VERSION ""

NS_ :

BS_:

BU_: PDM ATCCR ATCCF

BO_ 3221225472 VECTOR__INDEPENDENT_SIG_MSG: 0 Vector__XXX
 SG_ ATCCR_counterMsg465 : 0|4@1+ (1,0) [0|15] "" Vector__XXX
 SG_ PWM_wpPWM : 0|8@1+ (1,0) [0|255] "%" Vector__XXX
 SG_ PDM_fanLeftPWM : 0|8@1+ (1,0) [0|255] "%" Vector__XXX
 SG_ PDM_fanRightPWM : 0|8@1+ (1,0) [0|255] "%" Vector__XXX
 SG_ PDM_keepAliveVoltMin : 0|16@1- (0.001,0) [-32.768|32.767] "V" Vector__XXX
 SG_ PDM_keepAliveVoltAvg : 0|16@1- (0.001,0) [-32.768|32.767] "V" Vector__XXX
 SG_ PDM_keepAliveVoltMax : 0|16@1- (0.001,0) [-32.768|32.767] "V" Vector__XXX
 SG_ PDM_fuelVoltMin : 0|16@1- (0.001,0) [-32.768|32.767] "V" Vector__XXX
 SG_ PDM_fuelVoltAvg : 0|16@1- (0.001,0) [-32.768|32.767] "V" Vector__XXX
 SG_ PDM_fuelVoltMax : 0|16@1- (0.001,0) [-32.768|32.767] "V" Vector__XXX
 SG_ PDM_starterRelayVoltAvg : 0|16@1- (0.001,0) [-32.768|32.767] "V" Vector__XXX
 SG_ PDM_brakelightVoltAvg : 0|16@1- (0.001,0) [-32.768|32.767] "V" Vector__XXX
 SG_ PDM_dataVoltMin : 0|16@1- (0.001,0) [-32.768|32.767] "V" Vector__XXX
 SG_ PDM_dataVoltAvg : 0|16@1- (0.001,0) [-32.768|32.767] "V" Vector__XXX
 SG_ PDM_dataVoltMax : 0|16@1- (0.001,0) [-32.768|32.767] "V" Vector__XXX
 SG_ PDM_mainVoltMin : 0|16@1- (0.001,0) [-32.768|32.767] "V" Vector__XXX
 SG_ PDM_mainVoltAvg : 0|16@1- (0.001,0) [-32.768|32.767] "V" Vector__XXX
 SG_ PDM_mainVoltMax : 0|16@1- (0.001,0) [-32.768|32.767] "V" Vector__XXX
 SG_ PDM_wpVoltMin : 0|16@1- (0.001,0) [-32.768|32.767] "V" Vector__XXX
 SG_ PDM_wpVoltAvg : 0|16@1- (0.001,0) [-32.768|32.767] "V" Vector__XXX
 SG_ PDM_wpVoltMax : 0|16@1- (0.001,0) [-32.768|32.767] "V" Vector__XXX
 SG_ PDM_fanLeftVoltMin : 0|16@1- (0.001,0) [-32.768|32.767] "V" Vector__XXX
 SG_ PDM_fanLeftVoltAvg : 0|16@1- (0.001,0) [-32.768|32.767] "V" Vector__XXX
 SG_ PDM_fanLeftVoltMax : 0|16@1- (0.001,0) [-32.768|32.767] "V" Vector__XXX
 SG_ PDM_fanRightVoltMin : 0|16@1- (0.001,0) [-32.768|32.767] "V" Vector__XXX
 SG_ PDM_fanRightVoltAvg : 0|16@1- (0.001,0) [-32.768|32.767] "V" Vector__XXX
 SG_ PDM_fanRightVoltMax : 0|16@1- (0.001,0) [-32.768|32.767] "V" Vector__XXX
 SG_ PDM_pdmVoltMin : 0|16@1- (0.001,0) [-32.768|32.767] "V" Vector__XXX
 SG_ PDM_pdmVoltAvg : 0|16@1- (0.001,0) [-32.768|32.767] "V" Vector__XXX
 SG_ PDM_pdmVoltMax : 0|16@1- (0.001,0) [-32.768|32.767] "V" Vector__XXX
 SG_ PDM_fuelCurrentMin : 0|16@1- (0.01,0) [-327.68|327.67] "A" Vector__XXX
 SG_ PDM_fuelCurrentAvg : 0|16@1- (0.01,0) [-327.68|327.67] "A" Vector__XXX
 SG_ PDM_fuelCurrentMax : 0|16@1- (0.01,0) [-327.68|327.67] "A" Vector__XXX
 SG_ PDM_wpCurrentMin : 0|16@1- (0.01,0) [-327.68|327.67] "A" Vector__XXX
 SG_ PDM_wpCurrentAvg : 0|16@1- (0.01,0) [-327.68|327.67] "A" Vector__XXX
 SG_ PDM_wpCurrentMax : 0|16@1- (0.01,0) [-327.68|327.67] "A" Vector__XXX
 SG_ PDM_fanLeftCurrentMin : 0|16@1- (0.01,0) [-327.68|327.67] "A" Vector__XXX
 SG_ PDM_fanLeftCurrentAvg : 0|16@1- (0.01,0) [-327.68|327.67] "A" Vector__XXX
 SG_ PDM_fanLeftCurrentMax : 0|16@1- (1,0) [-32768|32767] "A" Vector__XXX
 SG_ PDM_fanRightCurrentMin : 0|16@1- (0.01,0) [-327.68|327.67] "A" Vector__XXX
 SG_ PDM_fanRightCurrentAvg : 0|16@1- (0.01,0) [-327.68|327.67] "A" Vector__XXX
 SG_ PDM_fanRightCurrentMax : 0|16@1- (0.01,0) [-327.68|327.67] "A" Vector__XXX
 SG_ ATCCF_counterMsg415 : 0|4@1+ (1,0) [0|15] "" Vector__XXX
 SG_ PDM_pdmCurrentMin : 0|16@1- (0.01,0) [-327.68|327.67] "A" Vector__XXX
 SG_ PDM_pdmCurrentAvg : 0|16@1- (0.01,0) [-327.68|327.67] "A" Vector__XXX
 SG_ PDM_pdmCurrentMax : 0|16@1- (0.01,0) [-327.68|327.67] "A" Vector__XXX
 SG_ PDM_boardTemp : 0|16@1- (0.1,0) [-3276.8|3276.7] "C" Vector__XXX

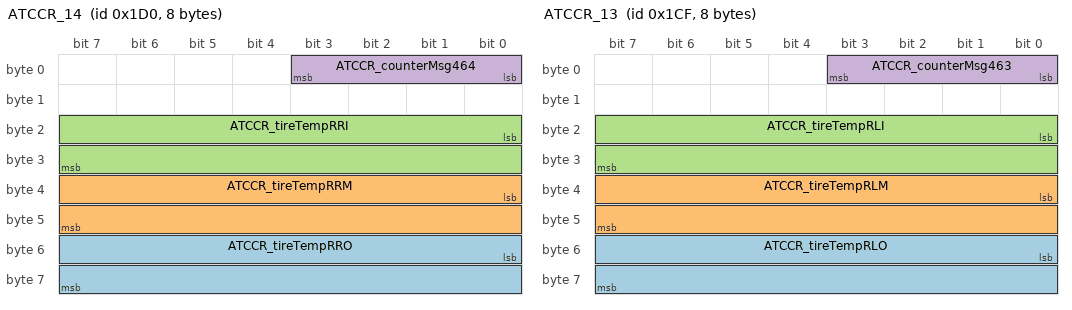
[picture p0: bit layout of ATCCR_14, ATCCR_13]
BO_ 464 ATCCR_14: 8 ATCCR
 SG_ ATCCR_tireTempRRO : 48|16@1- (0.1,0) [-3276.8|3276.7] "C" Vector__XXX
 SG_ ATCCR_tireTempRRM : 32|16@1- (0.1,0) [-3276.8|3276.7] "C" Vector__XXX
 SG_ ATCCR_tireTempRRI : 16|16@1- (0.1,0) [-3276.8|3276.7] "C" Vector__XXX
 SG_ ATCCR_counterMsg464 : 0|4@1+ (1,0) [0|15] "" Vector__XXX

BO_ 463 ATCCR_13: 8 ATCCR
 SG_ ATCCR_tireTempRLO : 48|16@1- (0.1,0) [-3276.8|3276.7] "C" Vector__XXX
 SG_ ATCCR_tireTempRLM : 32|16@1- (0.1,0) [-3276.8|3276.7] "C" Vector__XXX
 SG_ ATCCR_tireTempRLI : 16|16@1- (0.1,0) [-3276.8|3276.7] "C" Vector__XXX
 SG_ ATCCR_counterMsg463 : 0|4@1+ (1,0) [0|15] "" Vector__XXX

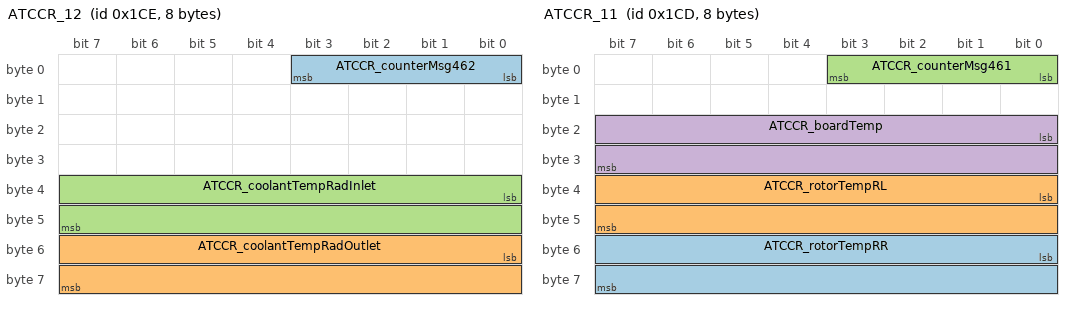
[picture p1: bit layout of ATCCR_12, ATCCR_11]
BO_ 462 ATCCR_12: 8 ATCCR
 SG_ ATCCR_counterMsg462 : 0|4@1+ (1,0) [0|15] "" Vector__XXX
 SG_ ATCCR_coolantTempRadOutlet : 48|16@1- (0.1,0) [-3276.8|3276.7] "C" Vector__XXX
 SG_ ATCCR_coolantTempRadInlet : 32|16@1- (0.1,0) [-3276.8|3276.7] "C" Vector__XXX

BO_ 461 ATCCR_11: 8 ATCCR
 SG_ ATCCR_rotorTempRR : 48|16@1- (0.1,0) [-3276.8|3276.7] "C" Vector__XXX
 SG_ ATCCR_rotorTempRL : 32|16@1- (0.1,0) [-3276.8|3276.7] "C" Vector__XXX
 SG_ ATCCR_counterMsg461 : 0|4@1+ (1,0) [0|15] "" Vector__XXX
 SG_ ATCCR_boardTemp : 16|16@1- (0.1,0) [-3276.8|3276.7] "C" Vector__XXX

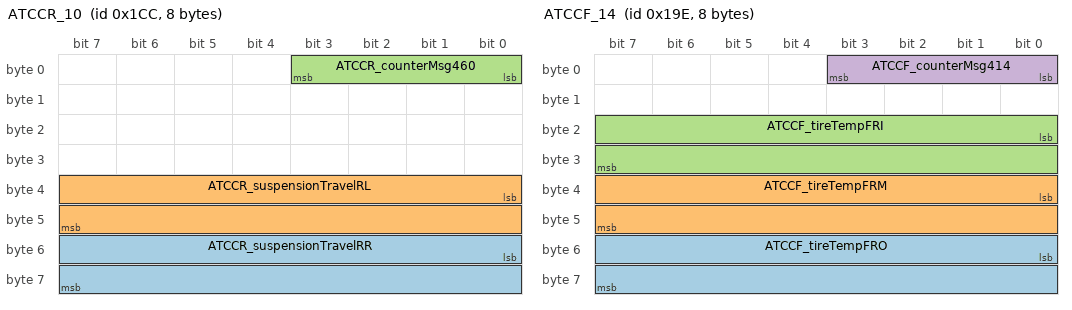
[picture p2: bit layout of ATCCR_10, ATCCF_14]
BO_ 460 ATCCR_10: 8 ATCCR
 SG_ ATCCR_suspensionTravelRR : 48|16@1- (0.001,0) [-32.768|32.767] "in" Vector__XXX
 SG_ ATCCR_suspensionTravelRL : 32|16@1- (0.001,0) [-32.768|32.767] "in" Vector__XXX
 SG_ ATCCR_counterMsg460 : 0|4@1+ (1,0) [0|15] "" Vector__XXX

BO_ 414 ATCCF_14: 8 ATCCF
 SG_ ATCCF_tireTempFRO : 48|16@1- (0.1,0) [-3276.8|3276.7] "C" Vector__XXX
 SG_ ATCCF_tireTempFRM : 32|16@1- (0.1,0) [-3276.8|3276.7] "C" Vector__XXX
 SG_ ATCCF_tireTempFRI : 16|16@1- (0.1,0) [-3276.8|3276.7] "C" Vector__XXX
 SG_ ATCCF_counterMsg414 : 0|4@1+ (1,0) [0|15] "" Vector__XXX

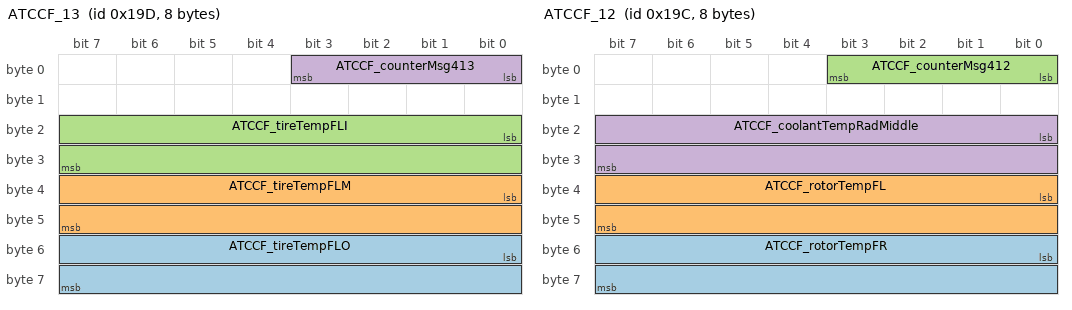
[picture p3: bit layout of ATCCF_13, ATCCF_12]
BO_ 413 ATCCF_13: 8 ATCCF
 SG_ ATCCF_tireTempFLO : 48|16@1- (0.1,0) [-3276.8|3276.7] "C" Vector__XXX
 SG_ ATCCF_tireTempFLM : 32|16@1- (0.1,0) [-3276.8|3276.7] "C" Vector__XXX
 SG_ ATCCF_tireTempFLI : 16|16@1- (0.1,0) [-3276.8|3276.7] "C" Vector__XXX
 SG_ ATCCF_counterMsg413 : 0|4@1+ (1,0) [0|15] "" Vector__XXX

BO_ 412 ATCCF_12: 8 ATCCF
 SG_ ATCCF_rotorTempFR : 48|16@1- (0.1,0) [-3276.8|3276.7] "C" Vector__XXX
 SG_ ATCCF_rotorTempFL : 32|16@1- (0.1,0) [-3276.8|3276.7] "C" Vector__XXX
 SG_ ATCCF_counterMsg412 : 0|4@1+ (1,0) [0|15] "" Vector__XXX
 SG_ ATCCF_coolantTempRadMiddle : 16|16@1- (0.1,0) [-3276.8|3276.7] "C" Vector__XXX

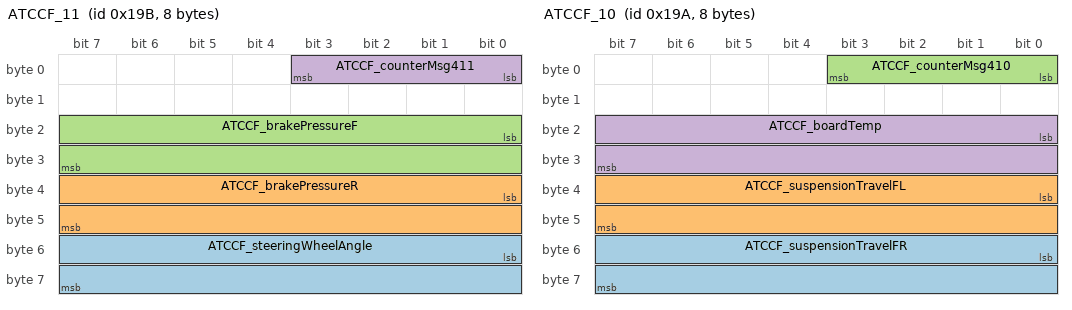
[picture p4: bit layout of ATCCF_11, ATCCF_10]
BO_ 411 ATCCF_11: 8 ATCCF
 SG_ ATCCF_steeringWheelAngle : 48|16@1- (0.1,0) [-3276.8|3276.7] "deg" Vector__XXX
 SG_ ATCCF_brakePressureR : 32|16@1- (0.1,0) [-3276.8|3276.7] "PSI" Vector__XXX
 SG_ ATCCF_brakePressureF : 16|16@1- (0.1,0) [-3276.8|3276.7] "PSI" Vector__XXX
 SG_ ATCCF_counterMsg411 : 0|4@1+ (1,0) [0|15] "" Vector__XXX

BO_ 410 ATCCF_10: 8 ATCCF
 SG_ ATCCF_suspensionTravelFR : 48|16@1- (0.001,0) [-32.768|32.767] "in" Vector__XXX
 SG_ ATCCF_suspensionTravelFL : 32|16@1- (0.001,0) [-32.768|32.767] "in" Vector__XXX
 SG_ ATCCF_counterMsg410 : 0|4@1+ (1,0) [0|15] "" Vector__XXX
 SG_ ATCCF_boardTemp : 16|16@1- (0.1,0) [-3276.8|3276.7] "C" Vector__XXX

CM_ BO_ 3221225472 "This is a message for not used signals, created by Vector CANdb++ DBC OLE DB Provider.";
CM_ SG_ 464 ATCCR_tireTempRRO "Tire Temp RRO";
CM_ SG_ 464 ATCCR_tireTempRRM "Tire Temp RRM";
CM_ SG_ 464 ATCCR_tireTempRRI "Tire Temp RRI";
CM_ SG_ 463 ATCCR_tireTempRLO "Tire Temp RLO";
CM_ SG_ 463 ATCCR_tireTempRLM "Tire Temp RLM";
CM_ SG_ 463 ATCCR_tireTempRLI "Tire Temp RLI";
CM_ SG_ 462 ATCCR_coolantTempRadOutlet "Coolant Temp Radiator Outlet";
CM_ SG_ 462 ATCCR_coolantTempRadInlet "Coolant Temp Radiator Inlet";
CM_ SG_ 461 ATCCR_rotorTempRR "Brake Temp RR";
CM_ SG_ 461 ATCCR_rotorTempRL "Brake Temp RL";
CM_ SG_ 461 ATCCR_boardTemp "Board Temp";
CM_ SG_ 460 ATCCR_suspensionTravelRR "Suspension Travel RR";
CM_ SG_ 460 ATCCR_suspensionTravelRL "Suspension Travel RL";
CM_ SG_ 414 ATCCF_tireTempFRO "Tire Temp FRO";
CM_ SG_ 414 ATCCF_tireTempFRM "Tire Temp FRM";
CM_ SG_ 414 ATCCF_tireTempFRI "Tire Temp FRI";
CM_ SG_ 413 ATCCF_tireTempFLO "Tire Temp FLO";
CM_ SG_ 413 ATCCF_tireTempFLM "Tire Temp FLM";
CM_ SG_ 413 ATCCF_tireTempFLI "Tire Temp FLI";
CM_ SG_ 412 ATCCF_rotorTempFR "Brake Temp FR";
CM_ SG_ 412 ATCCF_rotorTempFL "Brake Temp FL";
CM_ SG_ 412 ATCCF_coolantTempRadMiddle "Coolant Temp Radiator Middle";
CM_ SG_ 411 ATCCF_steeringWheelAngle "Steering Wheel Angle";
CM_ SG_ 411 ATCCF_brakePressureR "Brake Pressure R";
CM_ SG_ 411 ATCCF_brakePressureF "Brake Pressure F";
CM_ SG_ 410 ATCCF_suspensionTravelFR "Suspension Travel FR";
CM_ SG_ 410 ATCCF_suspensionTravelFL "Suspension Travel FL";
CM_ SG_ 410 ATCCF_boardTemp "Board Temp";
BA_DEF_  "BusType" STRING ;
BA_DEF_DEF_  "BusType" "CAN";
